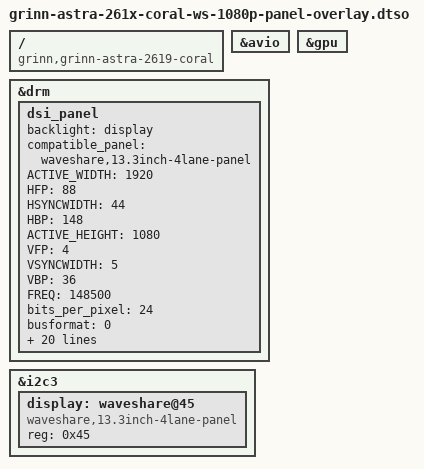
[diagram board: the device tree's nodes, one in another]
/dts-v1/;
/plugin/;

/ {
	compatible = "grinn,grinn-astra-2619-coral";
};

&avio {
	status = "okay";
};

&drm {
	status = "okay";

	dsi_panel {
		status = "okay";

		backlight = <&display>;
		compatible_panel="waveshare,13.3inch-4lane-panel";
		ACTIVE_WIDTH = <1920>;
		HFP = <88>;
		HSYNCWIDTH = <44>;
		HBP = <148>;
		ACTIVE_HEIGHT = <1080>;
		VFP = <4>;
		VSYNCWIDTH = <5>;
		VBP = <36>;
		FREQ = <148500>;
		bits_per_pixel = <24>;
		busformat = <0>;

		HTOTAL = <2200>;
		Lanes = /bits/ 8 <4>;
		Vid_mode = /bits/ 8 <2>;
		virtual_chan = /bits/ 8 <0>;
		Clk_Lane_Polarity = /bits/ 8 <0>;
		Data_Lane_Polarity = /bits/ 8 <0>;
		Recv_ack = /bits/ 8 <0>;
		Loosely_18 = /bits/ 8 <0>;
		H_polarity = /bits/ 8 <1>;
		V_Polarity = /bits/ 8 <1>;
		Data_Polarity = /bits/ 8 <1>;
		Eotp_tx = /bits/ 8 <1>;
		Eotp_rx = /bits/ 8 <0>;
		non-Continuous_clk = /bits/ 8 <0>;
		dpi_lp_cmd = /bits/ 8 <1>;
		Color_coding = /bits/ 8 <5>;
		Chunks = <0>;
		Null_Pkt = <0>;
		Byte_clk = <148500>;

		command = /bits/ 8 <0xFF  0x10 0x27  0x00  0x00>;
	};
};

&gpu {
	status = "okay";
};

&i2c3 {
	display: waveshare@45 {
		compatible = "waveshare,13.3inch-4lane-panel";
		status = "okay";
		reg = <0x45>;
	};
};
